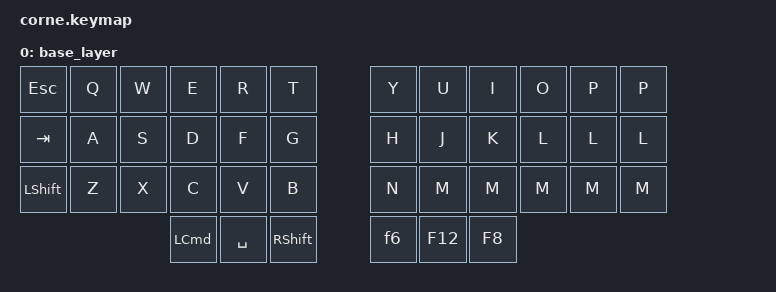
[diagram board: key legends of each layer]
// #include <behaviors.dtsi>
// #include <dt-bindings/zmk/keys.h>
// #include <dt-bindings/zmk/bt.h>
// / {
/ {
    keymap {
        compatible = "zmk,keymap";
            base_layer {
                            //////////////////////////////////////////////////////////////
                            //////////////////////////////////////////////////////////////
                            // Currently what keycaps have marked on them pre modification
                            // Row1
                            // F11, q,w,e,r,t    y, u, i, o, p , ESC
                            // Row2
                            // 8,a,s,d,f,g    h, j, k, l, ;, '
                            //Row3
                            //7,z,x,c,v,b    n, m, ,, ., /
                            //Row4
                            //f10, F7, F9, F6, F12, F8
                            //////////////////////////////////////////////////////////////
                            //////////////////////////////////////////////////////////////
                            bindings = <
                                //Row1
                                // 0            2           3           4           5           6                               7           8           9       10      11      12
                                &kp ESC         &kp Q       &kp W       &kp E       &kp R       &kp T                           &kp Y       &kp U       &kp I   &kp O   &kp P   &kp P
                                //Row2
                                // 13           14          15          16          17          18                              19          20          21      22      23      24
                                &kp TAB         &kp A       &kp S       &kp D       &kp F       &kp G                           &kp H       &kp J       &kp K   &kp L   &kp L   &kp L
                                //Row3
                                //  25          26          27          28          29          30                              31          32          33      34      35      36
                                &kp LSHIFT      &kp Z       &kp X       &kp C       &kp V       &kp B                           &kp N       &kp M       &kp M   &kp M   &kp M   &kp M
                                //Row4
                                                                                    37          38          39          49      50          51
                                                                                    &kp LCMD    &kp SPACE   &kp RSHFT   &kp f6  &kp F12     &kp F8    

                            >;
            };
    };

};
